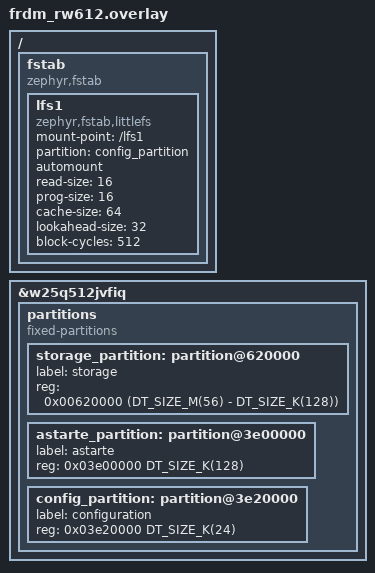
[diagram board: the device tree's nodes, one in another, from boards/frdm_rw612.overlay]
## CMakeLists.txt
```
# (C) Copyright 2024, SECO Mind Srl
#
# SPDX-License-Identifier: Apache-2.0

cmake_minimum_required(VERSION 3.20.0)

# add the sample specific private configuration
include(${CMAKE_SOURCE_DIR}/Utils.cmake)
concat_if_exists(${CMAKE_SOURCE_DIR}/private.conf EXTRA_CONF_FILE)

find_package(Zephyr REQUIRED HINTS $ENV{ZEPHYR_BASE})
project(astarte_app)

# create source files list
FILE(GLOB app_common_sources ${CMAKE_CURRENT_LIST_DIR}/src/*.c)
if(NOT CONFIG_WIFI)
    LIST(REMOVE_ITEM app_common_sources ${CMAKE_CURRENT_LIST_DIR}/src/wifi.c)
endif()
target_sources(app PRIVATE ${app_common_sources})
target_include_directories(app PRIVATE ${CMAKE_CURRENT_LIST_DIR}/include)

# add generated sources and includes for the interfaces
FILE(GLOB app_interfaces_sources ${CMAKE_CURRENT_LIST_DIR}/interfaces/*.c)
target_sources(app PRIVATE ${app_interfaces_sources})
target_include_directories(app PRIVATE ${CMAKE_CURRENT_LIST_DIR}/interfaces)
```

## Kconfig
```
# (C) Copyright 2024, SECO Mind Srl
#
# SPDX-License-Identifier: Apache-2.0
#
# This file is the application Kconfig entry point. All application Kconfig
# options can be defined here or included via other application Kconfig files.
# You can browse these options using the west targets menuconfig (terminal) or
# guiconfig (GUI).

menu "Zephyr"
source "Kconfig.zephyr"
endmenu

menu "Sample application"

config GET_CONFIG_FROM_FLASH
    bool "Collect the configuration from flash"
    help
        Collect the configuration from a file in the dedicated flash partition.

config WIFI_SSID
    string "WiFi SSID"
	depends on WIFI
    depends on !GET_CONFIG_FROM_FLASH
    default ""
	help
	  WiFi access point SSID.

config WIFI_PASSWORD
    string "WiFi password"
	depends on WIFI
    depends on !GET_CONFIG_FROM_FLASH
    default ""
    help
        WiFi access point password.

config DEVICE_ID
	string "Astarte device ID"
    depends on !GET_CONFIG_FROM_FLASH
    default ""
	help
	  Device ID to be used to connect to Astarte.

config CREDENTIAL_SECRET
    string "Astarte credential secret"
    depends on !GET_CONFIG_FROM_FLASH
    depends on !DEVICE_REGISTRATION
    default ""
    help
        The credential secret to be used to connect to Astarte.

config DEVICE_RX_THREAD_STACK_SIZE
    int "Device reception thread stack size (Bytes)"
    default 8192
    help
        Use this setting to change the size of the stack for the thread running the Astarte device
        receiving functionality.

config DEVICE_TX_THREAD_STACK_SIZE
    int "Device transmission thread stack size (Bytes)"
    default 4096
    help
        Use this setting to change the size of the stack for the thread running the Astarte device
        transmitting functionality.

config DEVICE_THREAD_PRIORITY
    int "Device thread(s) priority"
    default 0
    help
        Use this setting to change the priority of the receive and transmit threads running the
        Astarte device.

config DEVICE_POLL_PERIOD_MS
    int "Device thread polling period (ms)"
    default 100
    help
        Use this setting to change the polling period for the Astarte device.

config MQTT_CONNECTION_TIMEOUT_MS
    int "MQTT first polling timeout (ms)"
    default 3000
    help
        Use this setting to change the MQTT polling timeout for first polling operations.

config MQTT_POLL_TIMEOUT_MS
    int "MQTT subsequent polling timeout (ms)"
    default 500
    help
        Use this setting to change the MQTT polling timeout for subsequent polling operations.

config HTTP_TIMEOUT_MS
    int "HTTP operations timeout (ms)"
    default 3000
    help
        Use this setting to change the timeout for HTTP requests.

config DEVICE_OPERATIONAL_TIMEOUT
    int "Operational time in sedonds for which the device will stay connected to astarte"
    default 60
    depends on !DEVICE_INDIVIDUAL_TRANSMISSION
    depends on !DEVICE_OBJECT_TRANSMISSION
    depends on !DEVICE_PROPERTY_SET_TRANSMISSION
    depends on !DEVICE_PROPERTY_UNSET_TRANSMISSION
    help
        The device will stay connected to astarte for the specified number of seconds,
        after this time the device will be disconnected and the sample will end.
        This option gets automatically enabled when no transmission is configured to
        allow the device to wait for messages from the server.

menu "Registration"

config DEVICE_REGISTRATION
    bool "Enable device registration in the sample"
    default n
    help
        Use this setting to enable the registration of the device given a pairing jwt.
        The registration will use the defined jwt in ASTARTE_DEVICE_SDK_PAIRING_JWT.

endmenu

menu "Individual transmission"

config DEVICE_INDIVIDUAL_TRANSMISSION
    bool "Enable sample transmission of astarte individuals"
    default y
    help
        Use this setting to enable the transmission of astarte inviduals in the sample.

config DEVICE_INDIVIDUAL_TRANSMISSION_DELAY_SECONDS
    int "Device transmission delay (s)"
    default 10
    depends on DEVICE_INDIVIDUAL_TRANSMISSION
    help
        Use this setting to change how long to wait before sending individuals.
        This delay starts after the device connects to astarte: a delay of 0 means that all
        individuals will be sent just after a connection event.

endmenu

menu "Object transmission"

config DEVICE_OBJECT_TRANSMISSION
    bool "Enable sample transmission of astarte objects"
    default y
    help
        Use this setting to enable the transmission of astarte objects in the sample.

config DEVICE_OBJECT_TRANSMISSION_DELAY_SECONDS
    int "Device transmission delay (s)"
    default 10
    depends on DEVICE_OBJECT_TRANSMISSION
    help
        Use this setting to change how long to wait before sending objects.
        This delay starts after all individuals got sent: a delay of 0 means that all objects
        will be sent just after the individual got sent.

endmenu

menu "Property transmission"

config DEVICE_PROPERTY_SET_TRANSMISSION
    bool "Enable sample transmission of astarte properties set"
    default y
    help
        Use this setting to enable the transmission of astarte properties set in the sample.

config DEVICE_PROPERTY_SET_TRANSMISSION_DELAY_SECONDS
    int "Device transmission delay (s)"
    default 10
    depends on DEVICE_PROPERTY_SET_TRANSMISSION
    help
        Use this setting to change how long to wait before setting properties.
        This delay starts after all objects got sent: a delay of 0 means that all properties
        will be set just after the object got sent.

config DEVICE_PROPERTY_UNSET_TRANSMISSION
    bool "Enable sample transmission of astarte properties unset"
    default y
    help
        Use this setting to enable the transmission of astarte properties unset in the sample.

config DEVICE_PROPERTY_UNSET_TRANSMISSION_DELAY_SECONDS
    int "Send property unset transmission delay (s)"
    default 10
    depends on DEVICE_PROPERTY_UNSET_TRANSMISSION
    help
        Use this setting to change how long to wait before sending properties unsets.
        This delay starts after all properties got set: a delay of 0 means that all properties
        will be unset just after they got set.

endmenu

module = APP
module-str = APP
source "subsys/logging/Kconfig.template.log_config"

module = REGISTER
module-str = REGISTER
source "subsys/logging/Kconfig.template.log_config"

module = INDIVIDUAL
module-str = INDIVIDUAL
source "subsys/logging/Kconfig.template.log_config"

module = OBJECT
module-str = OBJECT
source "subsys/logging/Kconfig.template.log_config"

module = PROPERTY
module-str = PROPERTY
source "subsys/logging/Kconfig.template.log_config"

endmenu
```

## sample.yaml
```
# (C) Copyright 2024, SECO Mind Srl
#
# SPDX-License-Identifier: Apache-2.0
# This file is provided so that the application can be compiled using Twister,
# the Zephyr testing tool. In this file, multiple combinations can be specified,
# so that you can easily test all of them locally or in CI.

sample:
  description: Astarte application sample
  name: astarte-sample
tests:
  sample.default:
    build_only: true
    integration_platforms:
      - frdm_rw612
      - frdm_mcxn947/mcxn947/cpu0
      - mimxrt1060_evk@B/mimxrt1062/qspi
      - mimxrt1064_evk
      - stm32h573i_dk
      - native_sim
      - esp_wrover_kit/esp32/procpu
  sample.wifi:
    build_only: true
    extra_args: EXTRA_CONF_FILE="prj-wifi.conf"
    integration_platforms:
      - frdm_rw612
  sample.msv:
    build_only: true
    extra_args: CONF_FILE="prj-zephyr-msv.conf"
    integration_platforms:
      - frdm_rw612
      - stm32h573i_dk
```

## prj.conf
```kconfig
# (C) Copyright 2024, SECO Mind Srl
#
# SPDX-License-Identifier: Apache-2.0
#
# This is a Kconfig fragment which can be used to enable debug-related options
# in the application. See the README for more details.

# Astarte device SDK
CONFIG_ASTARTE_DEVICE_SDK=y
CONFIG_ASTARTE_DEVICE_SDK_HOSTNAME="."
# The two certificate tags are the same as the root CA is the same for Astarte API and MQTT broker.
CONFIG_ASTARTE_DEVICE_SDK_HTTPS_CA_CERT_TAG=1
CONFIG_ASTARTE_DEVICE_SDK_MQTTS_CA_CERT_TAG=1
CONFIG_ASTARTE_DEVICE_SDK_CLIENT_CERT_TAG=2
CONFIG_ASTARTE_DEVICE_SDK_PAIRING_JWT=""
CONFIG_ASTARTE_DEVICE_SDK_REALM_NAME="."

# Sample configuration
CONFIG_DEVICE_ID="......................"
CONFIG_CREDENTIAL_SECRET="............................................"

CONFIG_DEVICE_REGISTRATION=n
CONFIG_DEVICE_INDIVIDUAL_TRANSMISSION=y
CONFIG_DEVICE_OBJECT_TRANSMISSION=y
CONFIG_DEVICE_PROPERTY_SET_TRANSMISSION=y
CONFIG_DEVICE_PROPERTY_UNSET_TRANSMISSION=y

# Enable logging with floating point support
CONFIG_LOG=y
CONFIG_REQUIRES_FLOAT_PRINTF=y
CONFIG_CBPRINTF_FP_SUPPORT=y

# Increased stack size
CONFIG_MAIN_STACK_SIZE=8192

# Use custom heap
CONFIG_ASTARTE_DEVICE_SDK_ENABLE_HEAP=y

# Enable base64 encoding and decoding
CONFIG_BASE64=y

# Enable system hashmaps
CONFIG_SYS_HASH_MAP=y

# Enable JSON library
CONFIG_JSON_LIBRARY=y

# Enable entropy generator
CONFIG_ENTROPY_GENERATOR=y

# DNS resolver
CONFIG_DNS_RESOLVER=y
CONFIG_DNS_SERVER_IP_ADDRESSES=y
CONFIG_DNS_SERVER1="8.8.8.8" # Google DNS

# Base MbedTLS & heap configuration
CONFIG_MBEDTLS=y
CONFIG_MBEDTLS_BUILTIN=y
CONFIG_MBEDTLS_ENABLE_HEAP=y
CONFIG_MBEDTLS_HEAP_SIZE=55000

# Enable PSA Crypto Backend
CONFIG_PSA_CRYPTO=y
CONFIG_PSA_CRYPTO_ENABLE_ALL=y
CONFIG_MBEDTLS_PSA_CRYPTO_C=y

# TLS & X.509
CONFIG_MBEDTLS_SSL_MAX_CONTENT_LEN=8192
CONFIG_MBEDTLS_PEM_PARSE_C=y
CONFIG_MBEDTLS_PEM_WRITE_C=y
CONFIG_MBEDTLS_BASE64_C=y
CONFIG_MBEDTLS_PK_WRITE_C=y
CONFIG_MBEDTLS_SSL_PROTO_TLS1_2=y
CONFIG_MBEDTLS_SSL_SERVER_NAME_INDICATION=y
CONFIG_MBEDTLS_X509_USE_C=y
CONFIG_MBEDTLS_X509_CRT_PARSE_C=y
CONFIG_MBEDTLS_X509_CRL_PARSE_C=y
CONFIG_MBEDTLS_X509_CSR_PARSE_C=y
CONFIG_MBEDTLS_X509_CSR_WRITE_C=y
CONFIG_MBEDTLS_PKCS5_C=y
CONFIG_MBEDTLS_KEY_EXCHANGE_ECDHE_ECDSA_ENABLED=y
CONFIG_MBEDTLS_KEY_EXCHANGE_ECDHE_RSA_ENABLED=y

# Enable networking
CONFIG_NETWORKING=y

# Sockets
CONFIG_NET_SOCKETS=y
CONFIG_NET_SOCKETS_SOCKOPT_TLS=y

# Use DHCP for IPv4 and IPv6
CONFIG_NET_DHCPV4=y
CONFIG_NET_DHCPV6=y

# Generic networking options
CONFIG_NET_TX_STACK_SIZE=4096
CONFIG_NET_RX_STACK_SIZE=4096
CONFIG_NET_PKT_RX_COUNT=20
CONFIG_NET_PKT_TX_COUNT=20
CONFIG_NET_BUF_RX_COUNT=40
CONFIG_NET_BUF_TX_COUNT=40
CONFIG_NET_MAX_CONTEXTS=20
CONFIG_NET_MAX_CONN=6
CONFIG_NET_MGMT=y
CONFIG_NET_MGMT_EVENT=y
CONFIG_NET_IPV4=y
CONFIG_NET_IPV6=y
CONFIG_NET_TCP=y

# Enable HTTP client
CONFIG_HTTP_CLIENT=y

# MQTT options
CONFIG_MQTT_LIB=y
CONFIG_MQTT_LIB_TLS=y
CONFIG_MQTT_KEEPALIVE=60

# Enable flash
CONFIG_FLASH=y
CONFIG_FLASH_MAP=y
CONFIG_FLASH_PAGE_LAYOUT=y

# Enable storage
CONFIG_ZMS=y
CONFIG_ZMS_LOG_LEVEL_WRN=y

# Enable hash functions
CONFIG_SYS_HASH_FUNC32=y
CONFIG_SYS_HASH_FUNC32_MURMUR3=y

# Enable littlefs
CONFIG_FILE_SYSTEM=y
CONFIG_FILE_SYSTEM_LITTLEFS=y

# Enable UUID
CONFIG_UUID=y
CONFIG_UUID_V4=y
CONFIG_UUID_V5=y
CONFIG_UUID_BASE64=y

# Enable events
CONFIG_EVENTS=y

# Enable scoped cleanup helpers
CONFIG_SCOPE_CLEANUP_HELPERS=y
```

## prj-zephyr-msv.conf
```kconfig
# (C) Copyright 2024-2026, SECO Mind Srl
#
# SPDX-License-Identifier: Apache-2.0
#
# This is a Kconfig fragment which can be used to enable debug-related options
# in the application. See the README for more details.

# Astarte device SDK
CONFIG_ASTARTE_DEVICE_SDK=y
CONFIG_ASTARTE_DEVICE_SDK_HOSTNAME="."
# The two certificate tags are the same as the root CA is the same for Astarte API and MQTT broker.
CONFIG_ASTARTE_DEVICE_SDK_HTTPS_CA_CERT_TAG=1
CONFIG_ASTARTE_DEVICE_SDK_MQTTS_CA_CERT_TAG=1
CONFIG_ASTARTE_DEVICE_SDK_CLIENT_CERT_TAG=2
CONFIG_ASTARTE_DEVICE_SDK_PAIRING_JWT=""
CONFIG_ASTARTE_DEVICE_SDK_REALM_NAME="."

# Sample configuration
CONFIG_DEVICE_ID="......................"
CONFIG_CREDENTIAL_SECRET="............................................"

CONFIG_DEVICE_REGISTRATION=n
CONFIG_DEVICE_INDIVIDUAL_TRANSMISSION=y
CONFIG_DEVICE_OBJECT_TRANSMISSION=y
CONFIG_DEVICE_PROPERTY_SET_TRANSMISSION=y
CONFIG_DEVICE_PROPERTY_UNSET_TRANSMISSION=y

# Enable logging with floating point support
CONFIG_LOG=y
CONFIG_REQUIRES_FLOAT_PRINTF=y
CONFIG_CBPRINTF_FP_SUPPORT=y

# Increased stack size
CONFIG_MAIN_STACK_SIZE=8192

# Enable base64 encoding and decoding
CONFIG_BASE64=y

# Enable system hashmaps
CONFIG_SYS_HASH_MAP=y

# Enable JSON library
CONFIG_JSON_LIBRARY=y

# Enable entropy generator
CONFIG_ENTROPY_GENERATOR=y

# DNS resolver
CONFIG_DNS_RESOLVER=y
CONFIG_DNS_SERVER_IP_ADDRESSES=y
CONFIG_DNS_SERVER1="8.8.8.8" # Google DNS

# Base MbedTLS & heap configuration
CONFIG_MBEDTLS=y
CONFIG_MBEDTLS_BUILTIN=y
CONFIG_MBEDTLS_ENABLE_HEAP=y
CONFIG_MBEDTLS_HEAP_SIZE=55000

# Enable PSA Crypto Backend
CONFIG_PSA_CRYPTO=y
CONFIG_PSA_CRYPTO_ENABLE_ALL=y
CONFIG_MBEDTLS_USE_PSA_CRYPTO=y
CONFIG_MBEDTLS_PSA_CRYPTO_C=y

# TLS & X.509
CONFIG_MBEDTLS_SSL_MAX_CONTENT_LEN=8192
CONFIG_MBEDTLS_PEM_CERTIFICATE_FORMAT=y
CONFIG_MBEDTLS_PK_WRITE_C=y
CONFIG_MBEDTLS_SSL_PROTO_TLS1_2=y
CONFIG_MBEDTLS_SERVER_NAME_INDICATION=y
CONFIG_MBEDTLS_X509_CRL_PARSE_C=y
CONFIG_MBEDTLS_X509_CSR_PARSE_C=y
CONFIG_MBEDTLS_X509_CSR_WRITE_C=y
CONFIG_MBEDTLS_PKCS5_C=y
CONFIG_MBEDTLS_GENPRIME_ENABLED=y
CONFIG_MBEDTLS_KEY_EXCHANGE_ECDHE_ECDSA_ENABLED=y
CONFIG_MBEDTLS_KEY_EXCHANGE_ECDHE_RSA_ENABLED=y
CONFIG_MBEDTLS_ECDH_C=y
CONFIG_MBEDTLS_ECDSA_C=y
CONFIG_MBEDTLS_ECP_C=y
CONFIG_MBEDTLS_ECP_DP_SECP256R1_ENABLED=y

# Enable networking
CONFIG_NETWORKING=y

# Sockets
CONFIG_NET_SOCKETS=y
CONFIG_NET_SOCKETS_SOCKOPT_TLS=y

# Use DHCP for IPv4 and IPv6
CONFIG_NET_DHCPV4=y
CONFIG_NET_DHCPV6=y

# Generic networking options
CONFIG_NET_TX_STACK_SIZE=4096
CONFIG_NET_RX_STACK_SIZE=4096
CONFIG_NET_PKT_RX_COUNT=20
CONFIG_NET_PKT_TX_COUNT=20
CONFIG_NET_BUF_RX_COUNT=40
CONFIG_NET_BUF_TX_COUNT=40
CONFIG_NET_MAX_CONTEXTS=20
CONFIG_NET_MAX_CONN=6
CONFIG_NET_MGMT=y
CONFIG_NET_MGMT_EVENT=y
CONFIG_NET_IPV4=y
CONFIG_NET_IPV6=y
CONFIG_NET_TCP=y

# Enable HTTP client
CONFIG_HTTP_CLIENT=y

# MQTT options
CONFIG_MQTT_LIB=y
CONFIG_MQTT_LIB_TLS=y
CONFIG_MQTT_KEEPALIVE=60

# Enable flash
CONFIG_FLASH=y
CONFIG_FLASH_MAP=y
CONFIG_FLASH_PAGE_LAYOUT=y

# Enable storage
CONFIG_ZMS=y
CONFIG_ZMS_LOG_LEVEL_WRN=y

# Enable hash functions
CONFIG_SYS_HASH_FUNC32=y
CONFIG_SYS_HASH_FUNC32_MURMUR3=y

# Enable littlefs
CONFIG_FILE_SYSTEM=y
CONFIG_FILE_SYSTEM_LITTLEFS=y

# Enable UUID
CONFIG_UUID=y
CONFIG_UUID_V4=y
CONFIG_UUID_V5=y
CONFIG_UUID_BASE64=y

# Enable events
CONFIG_EVENTS=y
```

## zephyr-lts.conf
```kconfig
# (C) Copyright 2025, SECO Mind Srl
#
# SPDX-License-Identifier: Apache-2.0
#
# This is a Kconfig fragment which can be used to enable debug-related options
# in the application. See the README for more details.

# Astarte device SDK
CONFIG_ASTARTE_DEVICE_SDK=y
CONFIG_ASTARTE_DEVICE_SDK_HOSTNAME="."
# The two certificate tags are the same as the root CA is the same for Astarte API and MQTT broker.
CONFIG_ASTARTE_DEVICE_SDK_HTTPS_CA_CERT_TAG=1
CONFIG_ASTARTE_DEVICE_SDK_MQTTS_CA_CERT_TAG=1
CONFIG_ASTARTE_DEVICE_SDK_CLIENT_CERT_TAG=2
CONFIG_ASTARTE_DEVICE_SDK_PAIRING_JWT=""
CONFIG_ASTARTE_DEVICE_SDK_REALM_NAME="."

# Sample configuration
CONFIG_DEVICE_ID="......................"
CONFIG_CREDENTIAL_SECRET="............................................"

CONFIG_DEVICE_REGISTRATION=n
CONFIG_DEVICE_INDIVIDUAL_TRANSMISSION=y
CONFIG_DEVICE_OBJECT_TRANSMISSION=y
CONFIG_DEVICE_PROPERTY_SET_TRANSMISSION=y
CONFIG_DEVICE_PROPERTY_UNSET_TRANSMISSION=y

# Enable logging with floating point support
CONFIG_LOG=y
CONFIG_REQUIRES_FLOAT_PRINTF=y
CONFIG_CBPRINTF_FP_SUPPORT=y

# Increased stack size
CONFIG_MAIN_STACK_SIZE=8192

# Enable base64 encoding and decoding
CONFIG_BASE64=y

# Enable system hashmaps
CONFIG_SYS_HASH_MAP=y

# Enable JSON library
CONFIG_JSON_LIBRARY=y

# Enable entropy generator
CONFIG_ENTROPY_GENERATOR=y

# DNS resolver
CONFIG_DNS_RESOLVER=y
CONFIG_DNS_SERVER_IP_ADDRESSES=y
CONFIG_DNS_SERVER1="8.8.8.8" # Google DNS

# Base MbedTLS & heap configuration
CONFIG_MBEDTLS=y
CONFIG_MBEDTLS_BUILTIN=y
CONFIG_MBEDTLS_ENABLE_HEAP=y
CONFIG_MBEDTLS_HEAP_SIZE=55000

# Enable PSA Crypto Backend
CONFIG_PSA_CRYPTO=y
CONFIG_PSA_CRYPTO_ENABLE_ALL=y
CONFIG_MBEDTLS_USE_PSA_CRYPTO=y
CONFIG_MBEDTLS_PSA_CRYPTO_C=y

# TLS & X.509
CONFIG_MBEDTLS_SSL_MAX_CONTENT_LEN=16384
CONFIG_MBEDTLS_PEM_CERTIFICATE_FORMAT=y
CONFIG_MBEDTLS_PK_WRITE_C=y
CONFIG_MBEDTLS_SSL_PROTO_TLS1_2=y
CONFIG_MBEDTLS_SERVER_NAME_INDICATION=y
CONFIG_MBEDTLS_X509_CRL_PARSE_C=y
CONFIG_MBEDTLS_X509_CSR_PARSE_C=y
CONFIG_MBEDTLS_X509_CSR_WRITE_C=y
CONFIG_MBEDTLS_PKCS5_C=y
CONFIG_MBEDTLS_GENPRIME_ENABLED=y
CONFIG_MBEDTLS_KEY_EXCHANGE_ECDHE_ECDSA_ENABLED=y
CONFIG_MBEDTLS_KEY_EXCHANGE_ECDHE_RSA_ENABLED=y
CONFIG_MBEDTLS_ECDH_C=y
CONFIG_MBEDTLS_ECDSA_C=y
CONFIG_MBEDTLS_ECP_C=y
CONFIG_MBEDTLS_ECP_DP_SECP256R1_ENABLED=y

# Enable networking
CONFIG_NETWORKING=y

# Sockets
CONFIG_NET_SOCKETS=y
CONFIG_NET_SOCKETS_SOCKOPT_TLS=y

# Use DHCP for IPv4 and IPv6
CONFIG_NET_DHCPV4=y
CONFIG_NET_DHCPV6=y

# Generic networking options
CONFIG_NET_TX_STACK_SIZE=4096
CONFIG_NET_RX_STACK_SIZE=4096
CONFIG_NET_PKT_RX_COUNT=20
CONFIG_NET_PKT_TX_COUNT=20
CONFIG_NET_BUF_RX_COUNT=40
CONFIG_NET_BUF_TX_COUNT=40
CONFIG_NET_MAX_CONTEXTS=20
CONFIG_NET_MAX_CONN=6
CONFIG_NET_MGMT=y
CONFIG_NET_MGMT_EVENT=y
CONFIG_NET_IPV4=y
CONFIG_NET_IPV6=y
CONFIG_NET_TCP=y

# Enable HTTP client
CONFIG_HTTP_CLIENT=y

# MQTT options
CONFIG_MQTT_LIB=y
CONFIG_MQTT_LIB_TLS=y
CONFIG_MQTT_KEEPALIVE=60

# Enable flash
CONFIG_FLASH=y
CONFIG_FLASH_MAP=y
CONFIG_FLASH_PAGE_LAYOUT=y

# Enable NVS
CONFIG_NVS=y
CONFIG_NVS_LOG_LEVEL_WRN=y

# Enable littlefs
CONFIG_FILE_SYSTEM=y
CONFIG_FILE_SYSTEM_LITTLEFS=y
```

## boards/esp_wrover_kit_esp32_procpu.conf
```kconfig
# (C) Copyright 2026, SECO Mind Srl
#
# SPDX-License-Identifier: Apache-2.0

# Wi-Fi Configuration
CONFIG_WIFI=y
CONFIG_WIFI_ESP32=y

# increase network buffer size to avoid first connection attempt error
CONFIG_NET_BUF_TX_COUNT=64
CONFIG_NET_BUF_RX_COUNT=64

# ESP32 hardware random number generator is required for secure TLS
CONFIG_ENTROPY_ESP32_RNG=y

# Enable WROVER PSRAM
CONFIG_ESP_SPIRAM=y
# 2MB instead of deafult 256KB
CONFIG_ESP_SPIRAM_HEAP_SIZE=2097152

# Optimizations to save internal RAM used by the Wi-Fi driver
CONFIG_ESP_WIFI_HEAP_SPIRAM=y
CONFIG_ESP32_WIFI_NET_ALLOC_SPIRAM=y
CONFIG_ESP32_WIFI_RX_IRAM_OPT=n
CONFIG_ESP32_WIFI_IRAM_OPT=n

# Move MbedTLS heap to external RAM
CONFIG_MBEDTLS_HEAP_CUSTOM_SECTION=y

# Use a large log buffer size
CONFIG_LOG_BUFFER_SIZE=32768
```

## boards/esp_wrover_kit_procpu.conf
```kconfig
# (C) Copyright 2024, SECO Mind Srl
#
# SPDX-License-Identifier: Apache-2.0

# Enable wifi drivers
CONFIG_WIFI=y
CONFIG_WIFI_ESP32=y

# Added to prevent error with missing #include <ethernet/eth_stats.h> for esp_wifi_drv.c
# Adding this line will cause CMAKE Warning: No SOURCES given to Zephyr library: drivers__ethernet
# Just ignore.
CONFIG_NET_L2_ETHERNET=y

CONFIG_NET_CONFIG_SETTINGS=y

# Disable Astarte permanent storage for this board as no dedicated partition is present
CONFIG_ASTARTE_DEVICE_SDK_PERMANENT_STORAGE=n

# Enable ESP32 External RAM
CONFIG_ESP_SPIRAM=y
CONFIG_ESP32_WIFI_NET_ALLOC_SPIRAM=y
CONFIG_MBEDTLS_ENABLE_HEAP=n

# Use a small log buffer size
CONFIG_LOG_BUFFER_SIZE=4096
```

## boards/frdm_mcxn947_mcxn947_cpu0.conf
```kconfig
# (C) Copyright 2025, SECO Mind Srl
#
# SPDX-License-Identifier: Apache-2.0

# Disable Astarte permanent storage for this board as no dedicated partition is present
CONFIG_ASTARTE_DEVICE_SDK_PERMANENT_STORAGE=n
# Since there is no permanent storage, properties are of little use on this board
# Enabling transmission works but no value will be saved locally
CONFIG_DEVICE_PROPERTY_SET_TRANSMISSION=n
CONFIG_DEVICE_PROPERTY_UNSET_TRANSMISSION=n

# Use a small log buffer size
CONFIG_LOG_BUFFER_SIZE=16384

# An hardware entropy source is not enabled by default on this board, it should be evaluated why
CONFIG_TEST_RANDOM_GENERATOR=y

CONFIG_ETH_NXP_ENET_QOS_TX_BUFFER_DESCRIPTORS=8
CONFIG_ETH_NXP_ENET_QOS_RX_BUFFER_DESCRIPTORS=8

CONFIG_NET_TX_STACK_SIZE=16384
CONFIG_NET_RX_STACK_SIZE=16384
CONFIG_NET_PKT_RX_COUNT=40
CONFIG_NET_PKT_TX_COUNT=40
CONFIG_NET_MAX_CONTEXTS=40

CONFIG_NET_BUF_DATA_SIZE=512
CONFIG_NET_BUF_RX_COUNT=80
CONFIG_NET_BUF_TX_COUNT=80
```

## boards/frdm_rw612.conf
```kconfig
# (C) Copyright 2025, SECO Mind Srl
#
# SPDX-License-Identifier: Apache-2.0

# Enable the WiFi
CONFIG_WIFI_NXP=y

# Use a large log buffer size
CONFIG_LOG_BUFFER_SIZE=32768

# This board by default will expect the configuration to be present in flash
CONFIG_GET_CONFIG_FROM_FLASH=y
```

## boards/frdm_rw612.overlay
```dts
/*
 * (C) Copyright 2024, SECO Mind Srl
 *
 * SPDX-License-Identifier: Apache-2.0
 */

/delete-node/ &storage_partition;

/ {
    fstab {
        compatible = "zephyr,fstab";
        lfs1: lfs1 {
            compatible = "zephyr,fstab,littlefs";
            mount-point = "/lfs1";
            partition = <&config_partition>;
            automount;
            read-size = <16>;
            prog-size = <16>;
            cache-size = <64>;
            lookahead-size = <32>;
            block-cycles = <512>;
        };
    };
};

&w25q512jvfiq {
    partitions {
        compatible = "fixed-partitions";
        #address-cells = <1>;
        #size-cells = <1>;

        storage_partition: partition@620000 {
            label = "storage";
            reg = <0x00620000 (DT_SIZE_M(56) - DT_SIZE_K(128))>;
        };

        astarte_partition: partition@3e00000 {
            label = "astarte";
            reg = <0x03e00000 DT_SIZE_K(128)>;
        };

        config_partition: partition@3e20000 {
            label = "configuration";
            reg = <0x03e20000 DT_SIZE_K(24)>;
        };
    };
};
```

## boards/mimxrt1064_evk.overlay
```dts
/*
 * (C) Copyright 2024, SECO Mind Srl
 *
 * SPDX-License-Identifier: Apache-2.0
 */

/delete-node/ &storage_partition;

&is25wp064 {
	partitions {
		compatible = "fixed-partitions";
		#address-cells = <1>;
		#size-cells = <1>;

		storage_partition: partition@0 {
			label = "storage";
			reg = <0x00000000 DT_SIZE_M(4)>;
		};

		astarte_partition: partition@400000 {
			label = "astarte";
			reg = <0x00400000 DT_SIZE_M(4)>;
		};
	};
};
```

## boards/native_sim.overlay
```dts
/*
 * (C) Copyright 2024, SECO Mind Srl
 *
 * SPDX-License-Identifier: Apache-2.0
 */

&flash0 {
	partitions {
		compatible = "fixed-partitions";
        #address-cells = <1>;
        #size-cells = <1>;

		astarte_partition: partition@100000 {
			label = "astarte";
			reg = <0x00100000 DT_SIZE_K(128)>;
		};
	};
};
```

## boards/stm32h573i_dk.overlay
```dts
/*
 * (C) Copyright 2024, SECO Mind Srl
 *
 * SPDX-License-Identifier: Apache-2.0
 */

&flash0 {
	partitions {
		compatible = "fixed-partitions";
		#address-cells = <1>;
        #size-cells = <1>;

		astarte_partition: partition@100000 {
			label = "astarte";
			reg = <0x00100000 DT_SIZE_K(128)>;
		};
	};
};
```

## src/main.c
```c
/*
 * (C) Copyright 2024, SECO Mind Srl
 *
 * SPDX-License-Identifier: Apache-2.0
 */

#include <string.h>

#include <zephyr/data/json.h>
#include <zephyr/kernel.h>
#include <zephyr/logging/log.h>
#include <zephyr/net/http/client.h>
#include <zephyr/net/socket.h>
#include <zephyr/posix/arpa/inet.h>
#include <zephyr/toolchain.h>

#if (!defined(CONFIG_ASTARTE_DEVICE_SDK_DEVELOP_USE_NON_TLS_HTTP)                                  \
    || !defined(CONFIG_ASTARTE_DEVICE_SDK_DEVELOP_USE_NON_TLS_MQTT))
#include "ca_certificates.h"
#include <zephyr/net/tls_credentials.h>
#endif

#include <astarte_device_sdk/data.h>
#include <astarte_device_sdk/device.h>
#include <astarte_device_sdk/interface.h>
#include <astarte_device_sdk/mapping.h>
#include <astarte_device_sdk/pairing.h>

#ifdef CONFIG_WIFI
#include "wifi.h"
#else
#include "eth.h"
#endif

#include "utils.h"

#include "generated_interfaces.h"

#ifdef CONFIG_DEVICE_INDIVIDUAL_TRANSMISSION
#include "individual_send.h"
#endif
#ifdef CONFIG_DEVICE_OBJECT_TRANSMISSION
#include "object_send.h"
#endif
#if defined(CONFIG_DEVICE_PROPERTY_SET_TRANSMISSION)                                               \
    || defined(CONFIG_DEVICE_PROPERTY_UNSET_TRANSMISSION)
#include "property_send.h"
#endif
#ifdef CONFIG_DEVICE_REGISTRATION
#include "register.h"
#endif

#include "sample_config.h"

/************************************************
 * Constants, static variables and defines
 ***********************************************/

LOG_MODULE_REGISTER(main, CONFIG_APP_LOG_LEVEL); // NOLINT

#define THREAD_SLEEP_MS 500

// NOLINTBEGIN(cppcoreguidelines-avoid-non-const-global-variables)
K_MSGQ_DEFINE(device_msgq, sizeof(astarte_device_handle_t), 1, 1);

enum thread_flags
{
    THREAD_FLAGS_CONNECTED = 1U,
    THREAD_FLAGS_TX_COMPLETE,
    THREAD_FLAGS_RX_TERMINATION,
};
static atomic_t device_thread_flags;

K_THREAD_STACK_DEFINE(device_rx_thread_stack_area, CONFIG_DEVICE_RX_THREAD_STACK_SIZE);
static struct k_thread device_rx_thread_data;

K_THREAD_STACK_DEFINE(device_tx_thread_stack_area, CONFIG_DEVICE_TX_THREAD_STACK_SIZE);
static struct k_thread device_tx_thread_data;
// NOLINTEND(cppcoreguidelines-avoid-non-const-global-variables)

/************************************************
 * Static functions declaration
 ***********************************************/

/**
 * @brief Entry point for the Astarte device reception thread.
 *
 * @param device_id Device id for the Astarte device.
 * @param cred_secr/arg2 Unused argument or credential secret.
 * @param arg3 Unused argument.
 */
#if CONFIG_DEVICE_REGISTRATION
static void device_rx_thread_entry_point(void *device_id, void *arg2, void *arg3);
#else
static void device_rx_thread_entry_point(void *device_id, void *cred_secr, void *arg3);
#endif
/**
 * @brief Entry point for the Astarte device transmission thread.
 *
 * @param arg1 Unused argument.
 * @param arg2 Unused argument.
 * @param arg3 Unused argument.
 */
static void device_tx_thread_entry_point(void *arg1, void *arg2, void *arg3);
/**
 * @brief Handle an Astarte device event.
 *
 * @param event The received Astarte device event.
 */
static void handle_device_event(astarte_device_event_t *event);

/************************************************
 * Global functions definition
 ***********************************************/

int main(void)
{
    LOG_INF("Astarte device sample"); // NOLINT
    LOG_INF("Board: %s", CONFIG_BOARD); // NOLINT

    struct sample_config cfg_from_file = { 0 };
    sample_config_get(&cfg_from_file);
    LOG_INF("Configured device ID: %s", cfg_from_file.device_id); // NOLINT
#ifndef CONFIG_DEVICE_REGISTRATION
    LOG_INF("Configured credential secret: %s", cfg_from_file.credential_secret); // NOLINT
#endif
#ifdef CONFIG_WIFI
    LOG_INF("Configured WiFi SSID: %s", cfg_from_file.wifi_ssid); // NOLINT
    LOG_INF("Configured WiFi password: %s", cfg_from_file.wifi_pwd); // NOLINT
#endif

#ifdef CONFIG_WIFI
    LOG_INF("Initializing WiFi driver."); // NOLINT
    app_wifi_init();
    k_sleep(K_SECONDS(5));
    enum wifi_security_type sec = WIFI_SECURITY_TYPE_PSK;
    if (app_wifi_connect(cfg_from_file.wifi_ssid, sec, cfg_from_file.wifi_pwd) != 0) {
        LOG_ERR("Connectivity intialization failed!"); // NOLINT
        return -1;
    }
#else
    // Initialize Ethernet driver
    LOG_INF("Initializing Ethernet driver."); // NOLINT
    if (eth_connect() != 0) {
        LOG_ERR("Connectivity intialization failed!"); // NOLINT
        return -1;
    }
#endif

    // Add TLS certificate if required
#if (!defined(CONFIG_ASTARTE_DEVICE_SDK_DEVELOP_USE_NON_TLS_HTTP)                                  \
    || !defined(CONFIG_ASTARTE_DEVICE_SDK_DEVELOP_USE_NON_TLS_MQTT))
    tls_credential_add(CONFIG_ASTARTE_DEVICE_SDK_HTTPS_CA_CERT_TAG, TLS_CREDENTIAL_CA_CERTIFICATE,
        ca_certificate_root, sizeof(ca_certificate_root));
#endif

    // Spawn new rx thread for the Astarte device
#if CONFIG_DEVICE_REGISTRATION
    k_thread_create(&device_rx_thread_data, device_rx_thread_stack_area,
        K_THREAD_STACK_SIZEOF(device_rx_thread_stack_area), device_rx_thread_entry_point,
        cfg_from_file.device_id, NULL, NULL, CONFIG_DEVICE_THREAD_PRIORITY, 0, K_NO_WAIT);
#else
    k_thread_create(&device_rx_thread_data, device_rx_thread_stack_area,
        K_THREAD_STACK_SIZEOF(device_rx_thread_stack_area), device_rx_thread_entry_point,
        cfg_from_file.device_id, cfg_from_file.credential_secret, NULL,
        CONFIG_DEVICE_THREAD_PRIORITY, 0, K_NO_WAIT);
#endif
    // Spawn new tx thread for the Astarte device
    k_thread_create(&device_tx_thread_data, device_tx_thread_stack_area,
        K_THREAD_STACK_SIZEOF(device_tx_thread_stack_area), device_tx_thread_entry_point, NULL,
        NULL, NULL, CONFIG_DEVICE_THREAD_PRIORITY, 0, K_NO_WAIT);

    while (!atomic_test_bit(&device_thread_flags, THREAD_FLAGS_TX_COMPLETE)) {
#ifndef CONFIG_WIFI
        // Ensure the connectivity is still present
        if (eth_poll() != 0) {
            LOG_ERR("Failed polling Ethernet."); // NOLINT
            return -1;
        }
#endif
        k_sleep(K_MSEC(THREAD_SLEEP_MS));
    }

    // Ensure the Astarte tx thread has properly terminated and no more data is being sent.
    if (k_thread_join(&device_tx_thread_data, K_FOREVER) != 0) {
        LOG_ERR("Failed in waiting for the Astarte tx thread to terminate."); // NOLINT
    }

    // Signal to the Astarte rx thread that is should terminate.
    atomic_set_bit(&device_thread_flags, THREAD_FLAGS_RX_TERMINATION);

    // Wait for the Astarte rx thread to terminate.
    if (k_thread_join(&device_rx_thread_data, K_FOREVER) != 0) {
        LOG_ERR("Failed in waiting for the Astarte rx threads to terminate."); // NOLINT
    }

    LOG_INF("Astarte device sample finished."); // NOLINT
    k_sleep(K_MSEC(MSEC_PER_SEC));

    return 0;
}

/************************************************
 * Static functions definitions
 ***********************************************/

#if CONFIG_DEVICE_REGISTRATION
static void device_rx_thread_entry_point(void *device_id, void *arg2, void *arg3)
{
    ARG_UNUSED(arg2);
#else
static void device_rx_thread_entry_point(void *device_id, void *cred_secr, void *arg3)
{
#endif
    ARG_UNUSED(arg3);

    astarte_device_handle_t device = NULL;
    astarte_result_t res = ASTARTE_RESULT_OK;

    // Create a new instance of an Astarte device
#if CONFIG_DEVICE_REGISTRATION
    char cred_secr[ASTARTE_PAIRING_CRED_SECR_LEN + 1] = { 0 };
    if (register_device((char *) device_id, cred_secr) != 0) {
        LOG_ERR("Device registration failed, stopping rx thread"); // NOLINT
        k_msgq_put(&device_msgq, (void *) &device, K_FOREVER);
        return;
    }
#endif

    const astarte_interface_t *interfaces[] = {
        &org_astarteplatform_zephyr_examples_DeviceDatastream,
        &org_astarteplatform_zephyr_examples_ServerDatastream,
        &org_astarteplatform_zephyr_examples_DeviceAggregate,
        &org_astarteplatform_zephyr_examples_ServerAggregate,
        &org_astarteplatform_zephyr_examples_DeviceProperty,
        &org_astarteplatform_zephyr_examples_ServerProperty,
    };

    astarte_device_config_t device_config = { 0 };
    device_config.http_timeout_ms = CONFIG_HTTP_TIMEOUT_MS;
    device_config.mqtt_connection_timeout_ms = CONFIG_MQTT_CONNECTION_TIMEOUT_MS;
    device_config.mqtt_poll_timeout_ms = CONFIG_MQTT_POLL_TIMEOUT_MS;
    device_config.interfaces = interfaces;
    device_config.interfaces_size = ARRAY_SIZE(interfaces);
    memcpy(device_config.device_id, device_id, ASTARTE_DEVICE_ID_LEN + 1);
    memcpy(device_config.cred_secr, (const char *) cred_secr, ASTARTE_PAIRING_CRED_SECR_LEN + 1);

    res = astarte_device_new(&device_config, &device);
    if (res != ASTARTE_RESULT_OK) {
        LOG_ERR("Astarte device creation failure."); // NOLINT
        k_msgq_put(&device_msgq, (void *) &device, K_FOREVER);
        return;
    }

    res = astarte_device_connect(device);
    if (res != ASTARTE_RESULT_OK) {
        LOG_ERR("Astarte device connection failure."); // NOLINT
        k_msgq_put(&device_msgq, (void *) &device, K_FOREVER);
        return;
    }

    // Add the message to the queue for the transmit thread
    // NO_WAIT is used since we know we are the only therad writing
    k_msgq_put(&device_msgq, (void *) &device, K_NO_WAIT);

    while (!atomic_test_bit(&device_thread_flags, THREAD_FLAGS_RX_TERMINATION)) {
        astarte_device_event_t event = { 0 };

        astarte_result_t get_res
            = astarte_device_get_event(device, &event, K_MSEC(CONFIG_DEVICE_POLL_PERIOD_MS));

        if ((get_res != ASTARTE_RESULT_OK) && (get_res != ASTARTE_RESULT_TIMEOUT)) {
            // NOLINTNEXTLINE
            LOG_ERR("Error event retrieval failure: %s", astarte_result_to_name(get_res));
            continue;
        }

        if (get_res == ASTARTE_RESULT_OK) {
            handle_device_event(&event);
            astarte_device_event_cleanup(&event);
        }
    }

    LOG_INF("End of loop, disconnection imminent."); // NOLINT

    res = astarte_device_disconnect(device, K_SECONDS(10));
    if (res != ASTARTE_RESULT_OK) {
        LOG_ERR("Astarte device disconnection failure %s.", astarte_result_to_name(res)); // NOLINT
        return;
    }

    // we wait for a complete disconnection to avoid loosing some messages
    while (atomic_test_bit(&device_thread_flags, THREAD_FLAGS_CONNECTED)) {
        astarte_device_event_t event = { 0 };
        astarte_result_t get_res
            = astarte_device_get_event(device, &event, K_MSEC(CONFIG_DEVICE_POLL_PERIOD_MS));

        if ((get_res != ASTARTE_RESULT_OK) && (get_res != ASTARTE_RESULT_TIMEOUT)) {
            LOG_ERR("Error event retrieval failure: %s", astarte_result_to_name(get_res)); // NOLINT
            continue;
        }

        if (get_res == ASTARTE_RESULT_OK) {
            handle_device_event(&event);
            astarte_device_event_cleanup(&event);
        }
    }

    LOG_INF("Astarte device will now be destroyed."); // NOLINT
    res = astarte_device_destroy(device);
    if (res != ASTARTE_RESULT_OK) {
        LOG_ERR("Astarte device destroy failure."); // NOLINT
        return;
    }

    LOG_INF("Astarte thread will now be terminated."); // NOLINT

    k_sleep(K_MSEC(MSEC_PER_SEC));
}

static void device_tx_thread_entry_point(void *arg1, void *arg2, void *arg3)
{
    ARG_UNUSED(arg1);
    ARG_UNUSED(arg2);
    ARG_UNUSED(arg3);

    astarte_device_handle_t device = NULL;
    k_msgq_get(&device_msgq, (void *) &device, K_FOREVER);
    if (!device) {
        LOG_ERR("Received a failed device initialization, stopping transmission thread"); // NOLINT
        goto stop_transmission;
    }

    // wait for the device to be connected before sending data
    while (!atomic_test_bit(&device_thread_flags, THREAD_FLAGS_CONNECTED)) {
        k_sleep(K_MSEC(THREAD_SLEEP_MS));
    }

#ifdef CONFIG_DEVICE_INDIVIDUAL_TRANSMISSION
    // NOLINTNEXTLINE
    LOG_INF("Waiting %d seconds to send individuals.",
        CONFIG_DEVICE_INDIVIDUAL_TRANSMISSION_DELAY_SECONDS);
    k_sleep(K_SECONDS(CONFIG_DEVICE_INDIVIDUAL_TRANSMISSION_DELAY_SECONDS));
    sample_individual_transmission(device);
#endif
#ifdef CONFIG_DEVICE_OBJECT_TRANSMISSION
    // NOLINTNEXTLINE
    LOG_INF("Waiting %d seconds to send objects.", CONFIG_DEVICE_OBJECT_TRANSMISSION_DELAY_SECONDS);
    k_sleep(K_SECONDS(CONFIG_DEVICE_OBJECT_TRANSMISSION_DELAY_SECONDS));
    sample_object_transmission(device);
#endif
#ifdef CONFIG_DEVICE_PROPERTY_SET_TRANSMISSION
    // NOLINTNEXTLINE
    LOG_INF("Waiting %d seconds to set properties.",
        CONFIG_DEVICE_PROPERTY_SET_TRANSMISSION_DELAY_SECONDS);
    k_sleep(K_SECONDS(CONFIG_DEVICE_PROPERTY_SET_TRANSMISSION_DELAY_SECONDS));
    sample_property_set_transmission(device);
#endif
#ifdef CONFIG_DEVICE_PROPERTY_UNSET_TRANSMISSION
    // NOLINTNEXTLINE
    LOG_INF("Waiting %d seconds to unset properties.",
        CONFIG_DEVICE_PROPERTY_UNSET_TRANSMISSION_DELAY_SECONDS);
    k_sleep(K_SECONDS(CONFIG_DEVICE_PROPERTY_UNSET_TRANSMISSION_DELAY_SECONDS));
    sample_property_unset_transmission(device);
#endif

#if defined(CONFIG_DEVICE_INDIVIDUAL_TRANSMISSION) || defined(CONFIG_DEVICE_OBJECT_TRANSMISSION)   \
    || defined(CONFIG_DEVICE_PROPERTY_SET_TRANSMISSION)                                            \
    || defined(CONFIG_DEVICE_PROPERTY_UNSET_TRANSMISSION)
    LOG_INF("Transmission completed."); // NOLINT
#else
    // avoid unused device warnings
    (void) device;

    // NOLINTNEXTLINE
    LOG_INF("No transmission to perform. Keeping the device connected for %d seconds",
        CONFIG_DEVICE_OPERATIONAL_TIMEOUT);
    k_sleep(K_SECONDS(CONFIG_DEVICE_OPERATIONAL_TIMEOUT));
#endif

stop_transmission:
    // Signal to the main thread that the transmission is complete and the thread can be joined.
    atomic_set_bit(&device_thread_flags, THREAD_FLAGS_TX_COMPLETE);
}

static void handle_device_event(astarte_device_event_t *event)
{
    switch (event->type) {
        case ASTARTE_DEVICE_EVENT_ERROR: {
            // NOLINTNEXTLINE
            LOG_ERR("Astarte internal device error: %s (Context: %s)",
                astarte_result_to_name(event->data.error.result),
                event->data.error.context ? event->data.error.context : "Unknown");
            break;
        }
        case ASTARTE_DEVICE_EVENT_CONNECTED: {
            LOG_INF("Astarte device connected."); // NOLINT
            atomic_set_bit(&device_thread_flags, THREAD_FLAGS_CONNECTED);
            break;
        }
        case ASTARTE_DEVICE_EVENT_DISCONNECTED: {
            LOG_INF("Astarte device disconnected."); // NOLINT
            atomic_clear_bit(&device_thread_flags, THREAD_FLAGS_CONNECTED);
            break;
        }
        case ASTARTE_DEVICE_EVENT_DATASTREAM_INDIVIDUAL: {
            const char *interface_name
                = event->data.datastream_individual.base_event.interface_name;
            const char *path = event->data.datastream_individual.base_event.path;
            astarte_data_t individual = event->data.datastream_individual.data;
            // NOLINTNEXTLINE
            LOG_INF("Datastream individual event, interface: %s, path: %s", interface_name, path);
            utils_log_astarte_data(individual);
            break;
        }
        case ASTARTE_DEVICE_EVENT_DATASTREAM_OBJECT: {
            const char *interface_name = event->data.datastream_object.base_event.interface_name;
            const char *path = event->data.datastream_object.base_event.path;
            astarte_object_entry_t *entries = event->data.datastream_object.entries;
            size_t entries_length = event->data.datastream_object.entries_len;
            // NOLINTNEXTLINE
            LOG_INF("Datastream object event, interface: %s, path: %s", interface_name, path);
            utils_log_astarte_object(entries, entries_length);
            break;
        }
        case ASTARTE_DEVICE_EVENT_PROPERTY_SET: {
            const char *interface_name = event->data.property_set.base_event.interface_name;
            const char *path = event->data.property_set.base_event.path;
            astarte_data_t individual = event->data.property_set.data;
            // NOLINTNEXTLINE
            LOG_INF("Property set event, interface: %s, path: %s", interface_name, path);
            utils_log_astarte_data(individual);
            break;
        }
        case ASTARTE_DEVICE_EVENT_PROPERTY_UNSET: {
            const char *interface_name = event->data.property_unset.interface_name;
            const char *path = event->data.property_unset.path;
            // NOLINTNEXTLINE
            LOG_INF("Property unset event, interface: %s, path: %s", interface_name, path);
            break;
        }
        default: {
            break;
        }
    }
}
```

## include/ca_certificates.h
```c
/*
 * (C) Copyright 2024, SECO Mind Srl
 *
 * SPDX-License-Identifier: Apache-2.0
 */

#ifndef CA_CERTIFICATES_H
#define CA_CERTIFICATES_H

/* By default only certificates in DER format are supported. If you want to use
 * certificate in PEM format, you can enable support for it in Kconfig.
 */

static const unsigned char ca_certificate_root[]
    = { "-----BEGIN CERTIFICATE-----\n"
        "MIIF9DCCA9ygAwIBAgIRAPJLbRf52a18scn+p4eCaZ8wDQYJKoZIhvcNAQELBQAw\n"
        "TzELMAkGA1UEBhMCVVMxKTAnBgNVBAoTIEludGVybmV0IFNlY3VyaXR5IFJlc2Vh\n"
        "cmNoIEdyb3VwMRUwEwYDVQQDEwxJU1JHIFJvb3QgWDEwHhcNMjYwNTEzMDAwMDAw\n"
        "WhcNMzIwOTAyMjM1OTU5WjAuMQswCQYDVQQGEwJVUzENMAsGA1UEChMESVNSRzEQ\n"
        "MA4GA1UEAxMHUm9vdCBZUjCCAiIwDQYJKoZIhvcNAQEBBQADggIPADCCAgoCggIB\n"
        "ANvGJnN78CTJdWL3+eGfsLN5TrNBJs+VH9hRXqRbwxu9sGNiB0BD1fcOxbSUQCJI\n"
        "M1xE13Db+5Cw1w0s0EBYsvuIP/6joF0w8cuImbgR1OGgYbSQ4OpzI+DG8SGuTlcE\n"
        "873OCS+kh3srlo6vl43M5OJg4Aeo1sfHp6kTJDoIiFBNJAY+OKfX/FUvYKuhjT+n\n"
        "o49lmqmupSBI5PkBQiqrEGtWU5uxU/cQWHGu8jSjFBznZqvbNPLMXMLFxCb3WTfr\n"
        "JBXXjqvWG+v4bjzxjjeAtOlU7qarRDvNOyAuQYLln904M+faKx8hnLCpJ15ZqaEg\n"
        "cNlY+9MMWcC5yvL2A2j3l9+2buggZX+dOE91zYmIdawTvSZuVvlbRrAlLxIB6pwM\n"
        "BjneXCjYQ8+3BCCjssbSNpZU3hTcBDdhfAlEDlYr6pEatnMdmDT5BqnKC92bd0Eh\n"
        "M1fbLHioLccLCuievT8ZkPhZrq7Mii7gNXAcUEAR8+lzYal+9zTg7C5DALyVOeG/\n"
        "CqfRAMn1KSHCR0NSA6P8tn/mGRlnCct5rtVCLnVySVpU6H1qGg3DgTOuskf8eahT\n"
        "MiYbI5ezPJmO5ertalskQ1utp74+eDy92PI4ftHKTbq9IWhH4YZKh3WnJEIt+oQv\n"
        "lYZbY8tpEroKrFB6PFGzrJIDRyts4HqvuH52RFj2zv/BAgMBAAGjgeswgegwDgYD\n"
        "VR0PAQH/BAQDAgEGMBMGA1UdJQQMMAoGCCsGAQUFBwMBMA8GA1UdEwEB/wQFMAMB\n"
        "Af8wHQYDVR0OBBYEFN7nW2DQIm1AKH0/DQH+pLVStFGUMB8GA1UdIwQYMBaAFHm0\n"
        "WeZ7tuXkAXOACIjIGlj26ZtuMDIGCCsGAQUFBwEBBCYwJDAiBggrBgEFBQcwAoYW\n"
        "aHR0cDovL3gxLmkubGVuY3Iub3JnLzATBgNVHSAEDDAKMAgGBmeBDAECATAnBgNV\n"
        "HR8EIDAeMBygGqAYhhZodHRwOi8veDEuYy5sZW5jci5vcmcvMA0GCSqGSIb3DQEB\n"
        "CwUAA4ICAQA8spSI95KKfn2W6GMmDpHBJSPaLbsS3W93cijJCRCYAc1fsJgL1FIL\n"
        "7C0C9ecPOdcwB2fi0Dk2p94j9iTJCxmt5CFSKLRWwnXT2MMSXexVxqoVB79BdWPx\n"
        "VXETkVme/qYSAuKVHh5Ps+5BixgmwS1JkjSAc+MfrUbNssVEEnH0aEiAh+rotXAV\n"
        "JSP/Ye7LJPEwD9DWG72vVWbhAcuOf5OLjz57Ctk7MgQHynZ7+PlHJtajroCaIbtC\n"
        "r6tcZZaAwUQm+jQyeWdV+2hv9deOYFmKeQyjjcSrN5Nadrw+L9DZJLbA1HqeNvLh\n"
        "BgqpP0fvJq2N6EtD574N6eMI7uMsJTnji2UDz9el5XLSv9fqJMuDQtYVb2oTNoKp\n"
        "oUqhxPVC0aq4eG5MESaIdn8b5ZGSSeAJLMHXljEdlNza+ncfkviXk1POLnnFdvx8\n"
        "/gk6M374WbLWFXw8N141B/Rl/tINGfl1TxOIiqtiMYkL02RSGb1kq34BL9NPP27z\n"
        "RGMuHGnzS3hFIrRTfKxrzUZ9RzQWzEG3K6fJ3r2nqSltkeytis9DIBoFY9VmVyjL\n"
        "M71DMi+y1+TRSJVClEMwvA4yL++7q9XZx5r5wBRWB4kQTKH5qyoZnDw7iiuh1lID\n"
        "yDFx8r7i9vIJU5HS3moZLkYWAOilMaV9N56A9Bgb6dNcHkvg3NoaYA==\n"
        "-----END CERTIFICATE-----\n" };

#endif /* CA_CERTIFICATES_H */
```

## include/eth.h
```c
/*
 * (C) Copyright 2024, SECO Mind Srl
 *
 * SPDX-License-Identifier: Apache-2.0
 */

#ifndef ETH_H
#define ETH_H

/**
 * @brief Blocking function to connect the device to internet.
 *
 * @note This is not actually initializing the ethernet module which is intialized by default.
 *
 * @return 0 upon success, -1 otherwise.
 */
int eth_connect(void);

/**
 * @brief Poll the Ethernet driver, ensuring a connection is present.
 *
 * @note This function will block when connectivity is not present.
 */
void eth_poll(void);

#endif /* ETH_H */
```

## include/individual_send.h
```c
/*
 * (C) Copyright 2024, SECO Mind Srl
 *
 * SPDX-License-Identifier: Apache-2.0
 */

#ifndef INDIVIDUAL_SEND_H
#define INDIVIDUAL_SEND_H

#include <astarte_device_sdk/device.h>

void sample_individual_transmission(astarte_device_handle_t device);

#endif // INDIVIDUAL_SEND_H
```

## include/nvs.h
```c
/*
 * (C) Copyright 2024, SECO Mind Srl
 *
 * SPDX-License-Identifier: Apache-2.0
 */

#ifndef NVS_H
#define NVS_H

#include <stdbool.h>
#include <stddef.h>

/**
 * @brief NVS driver.
 *
 * @return 0 upon success, -1 otherwise.
 */
int nvs_init(void);

/**
 * @brief Check if credential secret is already stored in NVS.
 *
 * @param[out] res Set to true if found, false if not, unchanged upon error.
 * @return 0 upon success, -1 following an internal error.
 */
int nvs_has_cred_secr(bool *res);

/**
 * @brief Get the stored credential secret.
 *
 * @param[out] cred_secr Buffer where the credential secret will be stored.
 * @param[in] cred_secr_size Size of the credential secret buffer.
 * @return 0 upon success, -1 otherwise.
 */
int nvs_get_cred_secr(char *cred_secr, size_t cred_secr_size);

/**
 * @brief Get the stored credential secret.
 *
 * @param[out] cred_secr Credential scret to store.
 * @return 0 upon success, -1 otherwise.
 */
int nvs_store_cred_secr(char *cred_secr);

#endif /* NVS_H */
```

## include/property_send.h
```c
/*
 * (C) Copyright 2024, SECO Mind Srl
 *
 * SPDX-License-Identifier: Apache-2.0
 */

#ifndef PROPERTY_SEND_H
#define PROPERTY_SEND_H

#include <astarte_device_sdk/device.h>

void sample_property_set_transmission(astarte_device_handle_t device);

void sample_property_unset_transmission(astarte_device_handle_t device);

#endif // PROPERTY_SEND_H
```

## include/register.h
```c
/*
 * (C) Copyright 2024, SECO Mind Srl
 *
 * SPDX-License-Identifier: Apache-2.0
 */

#ifndef REGISTER_H
#define REGISTER_H

#include <astarte_device_sdk/device.h>

int register_device(char device_id[static ASTARTE_DEVICE_ID_LEN + 1],
    char cred_secr[static ASTARTE_PAIRING_CRED_SECR_LEN + 1]);

#endif // REGISTER_H
```

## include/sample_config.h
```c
/*
 * (C) Copyright 2025, SECO Mind Srl
 *
 * SPDX-License-Identifier: Apache-2.0
 */

#ifndef SAMPLE_CONFIG_H
#define SAMPLE_CONFIG_H

#include <stdbool.h>
#include <stddef.h>

#include <astarte_device_sdk/device.h>

#if defined(CONFIG_WIFI)
#define SAMPLE_CONFIG_WIFI_MAX_STRINGS 255
#endif

struct sample_config
{
    char device_id[ASTARTE_DEVICE_ID_LEN + 1];
#if !defined(CONFIG_DEVICE_REGISTRATION)
    char credential_secret[ASTARTE_PAIRING_CRED_SECR_LEN + 1];
#endif
#if defined(CONFIG_WIFI)
    char wifi_ssid[SAMPLE_CONFIG_WIFI_MAX_STRINGS];
    char wifi_pwd[SAMPLE_CONFIG_WIFI_MAX_STRINGS];
#endif
};

int sample_config_get(struct sample_config *cfg);

#endif /* SAMPLE_CONFIG_H */
```

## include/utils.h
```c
/*
 * (C) Copyright 2024, SECO Mind Srl
 *
 * SPDX-License-Identifier: Apache-2.0
 */

#ifndef UTILS_H
#define UTILS_H

/**
 * @file utils.h
 * @brief Contains some common utilities for the samples.
 *
 * @details This file contains a function to "pretty print" an Astarte individual and a set of
 * standard data to use when streaming datastreams or setting properties in the samples.
 * The standard data contains an element for each possible Astarte type. This allows the samples
 * to demonstrate transmission of all existing Astarte types.
 * Each data element is paired to a string representing a mapping endpoint for the interfaces to
 * be used in the samples.
 */

#include <astarte_device_sdk/data.h>
#include <astarte_device_sdk/object.h>
#include <stdint.h>

#define UTILS_DATA_ELEMENTS 14

extern const uint8_t utils_binary_blob_data[8];
extern const uint8_t *const utils_binary_blobs_data[2];
extern const size_t utils_binary_blobs_sizes_data[2];
extern const bool utils_boolean_data;
extern const bool utils_boolean_array_data[3];
extern const int64_t utils_unix_time_data;
extern const int64_t utils_unix_time_array_data[1];
extern const double utils_double_data;
extern const double utils_double_array_data[2];
extern const int32_t utils_integer_data;
extern const int32_t utils_integer_array_data[3];
extern const int64_t utils_longinteger_data;
extern const int64_t utils_longinteger_array_data[3];
extern const char utils_string_data[];
extern const char *const utils_string_array_data[2];

/**
 * @brief Pretty print to the log output an Astarte data.
 *
 * @param[in] data The data to log
 */
void utils_log_astarte_data(astarte_data_t data);

void utils_log_astarte_object(astarte_object_entry_t *entries, size_t entries_len);

#endif /* UTILS_H */
```

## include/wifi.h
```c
/*
 * (C) Copyright 2024, SECO Mind Srl
 *
 * SPDX-License-Identifier: Apache-2.0
 */

#ifndef WIFI_H
#define WIFI_H

#include <zephyr/net/wifi.h>

/**
 * @brief Initialize the wifi driver
 */
void app_wifi_init(void);

/**
 * @brief Connect the wifi to an SSID
 */
int app_wifi_connect(const char *ssid, enum wifi_security_type sec, const char *psk);

#endif /* WIFI_H */
```
